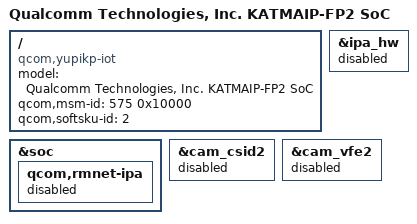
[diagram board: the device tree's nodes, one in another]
// SPDX-License-Identifier: BSD-3-Clause
/*
 * Copyright (c) Qualcomm Technologies, Inc. and/or its subsidiaries.
 */

#include "katmai-fp2.dtsi"

/ {
	model = "Qualcomm Technologies, Inc. KATMAIP-FP2 SoC";
	compatible = "qcom,yupikp-iot";
	qcom,msm-id = <575 0x10000>;
	qcom,softsku-id = <2>;
};

&soc {
	qcom,rmnet-ipa {
		status = "disabled";
	};
};

&ipa_hw {
	status = "disabled";
};

&cam_csid2 {
	status = "disabled";
};

&cam_vfe2 {
	status = "disabled";
};
